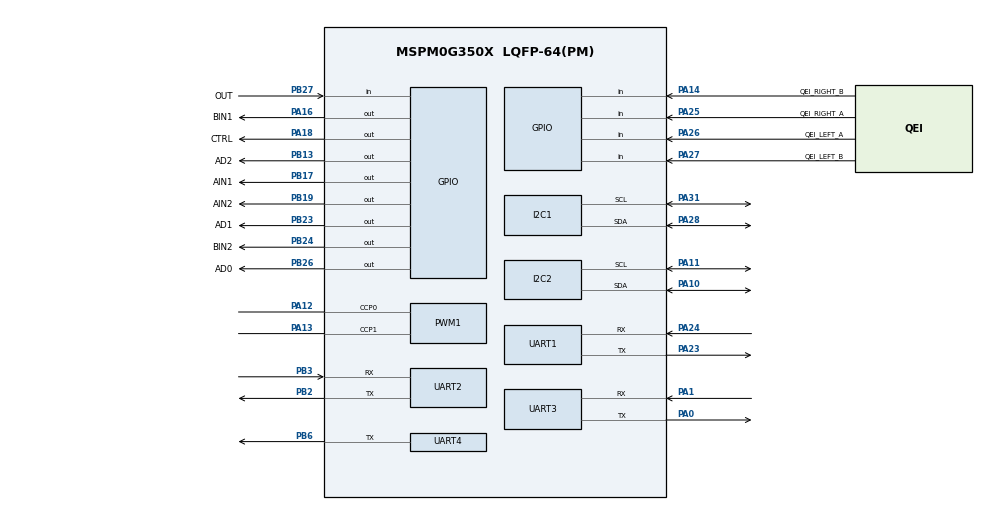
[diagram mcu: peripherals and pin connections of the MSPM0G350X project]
/**
 * @cliArgs --device "MSPM0G350X" --part "Default" --package "LQFP-64(PM)" --product "mspm0_sdk@2.11.00.07"
 * @versions {"tool":"1.26.2+4477"}
 */

/**
 * Import the modules used in this configuration.
 */
const GPIO   = scripting.addModule("/ti/driverlib/GPIO", {}, false);
const GPIO1  = GPIO.addInstance();
const GPIO2  = GPIO.addInstance();
const GPIO3  = GPIO.addInstance();
const GPIO4  = GPIO.addInstance();
const I2C    = scripting.addModule("/ti/driverlib/I2C", {}, false);
const I2C1   = I2C.addInstance();
const I2C2   = I2C.addInstance();
const PWM    = scripting.addModule("/ti/driverlib/PWM", {}, false);
const PWM1   = PWM.addInstance();
const SYSCTL = scripting.addModule("/ti/driverlib/SYSCTL");
const TIMER  = scripting.addModule("/ti/driverlib/TIMER", {}, false);
const TIMER1 = TIMER.addInstance();
const TIMER2 = TIMER.addInstance();
const UART   = scripting.addModule("/ti/driverlib/UART", {}, false);
const UART1  = UART.addInstance();
const UART2  = UART.addInstance();
const UART3  = UART.addInstance();
const UART4  = UART.addInstance();

/**
 * Write custom configuration values to the imported modules.
 */
GPIO1.$name                         = "GPIO_MOTOR";
GPIO1.associatedPins.create(4);
GPIO1.associatedPins[0].$name       = "AIN1";
GPIO1.associatedPins[0].pin.$assign = "PB17";
GPIO1.associatedPins[1].$name       = "AIN2";
GPIO1.associatedPins[1].pin.$assign = "PB19";
GPIO1.associatedPins[2].$name       = "BIN1";
GPIO1.associatedPins[2].pin.$assign = "PA16";
GPIO1.associatedPins[3].$name       = "BIN2";
GPIO1.associatedPins[3].pin.$assign = "PB24";

const Board = scripting.addModule("/ti/driverlib/Board", {}, false);

GPIO2.$name                         = "GPIO_SENSOR";
GPIO2.associatedPins.create(4);
GPIO2.associatedPins[0].$name       = "AD0";
GPIO2.associatedPins[0].pin.$assign = "PB26";
GPIO2.associatedPins[1].$name       = "AD1";
GPIO2.associatedPins[1].pin.$assign = "PB23";
GPIO2.associatedPins[2].$name       = "AD2";
GPIO2.associatedPins[2].pin.$assign = "PB13";
GPIO2.associatedPins[3].$name       = "OUT";
GPIO2.associatedPins[3].direction   = "INPUT";
GPIO2.associatedPins[3].pin.$assign = "PB27";

GPIO3.$name                              = "GPIO_ENCODER";
GPIO3.associatedPins.create(4);
GPIO3.associatedPins[0].$name            = "QEI_LEFT_A";
GPIO3.associatedPins[0].direction        = "INPUT";
GPIO3.associatedPins[0].interruptEn      = true;
GPIO3.associatedPins[0].internalResistor = "PULL_UP";
GPIO3.associatedPins[0].polarity         = "RISE_FALL";
GPIO3.associatedPins[0].pin.$assign      = "PA26";
GPIO3.associatedPins[1].$name            = "QEI_RIGHT_A";
GPIO3.associatedPins[1].direction        = "INPUT";
GPIO3.associatedPins[1].interruptEn      = true;
GPIO3.associatedPins[1].internalResistor = "PULL_UP";
GPIO3.associatedPins[1].polarity         = "RISE_FALL";
GPIO3.associatedPins[1].pin.$assign      = "PA25";
GPIO3.associatedPins[2].$name            = "QEI_LEFT_B";
GPIO3.associatedPins[2].direction        = "INPUT";
GPIO3.associatedPins[2].internalResistor = "PULL_UP";
GPIO3.associatedPins[2].pin.$assign      = "PA27";
GPIO3.associatedPins[3].$name            = "QEI_RIGHT_B";
GPIO3.associatedPins[3].direction        = "INPUT";
GPIO3.associatedPins[3].internalResistor = "PULL_UP";
GPIO3.associatedPins[3].pin.$assign      = "PA14";

GPIO4.$name                         = "GPIO_ELECTROMAGNET";
GPIO4.associatedPins[0].$name       = "CTRL";
GPIO4.associatedPins[0].pin.$assign = "PA18";

I2C1.$name                             = "OLED";
I2C1.basicEnableController             = true;
I2C1.advDigitalGlitchFilter            = "CLOCKS_1";
I2C1.advControllerRXFIFOTRIG           = "BYTES_8";
I2C1.advControllerTXFIFOTRIG           = "BYTES_7";
I2C1.enableDMAEvent1                   = false;
I2C1.enableDMAEvent2                   = false;
I2C1.peripheral.$assign                = "I2C0";
I2C1.peripheral.sdaPin.$assign         = "PA28";
I2C1.peripheral.sclPin.$assign         = "PA31";
I2C1.sdaPinConfig.hideOutputInversion  = scripting.forceWrite(false);
I2C1.sdaPinConfig.onlyInternalResistor = scripting.forceWrite(false);
I2C1.sdaPinConfig.passedPeripheralType = scripting.forceWrite("Digital");
I2C1.sdaPinConfig.$name                = "ti_driverlib_gpio_GPIOPinGeneric2";
I2C1.sdaPinConfig.enableConfig         = true;
I2C1.sdaPinConfig.internalResistor     = "PULL_UP";
I2C1.sclPinConfig.hideOutputInversion  = scripting.forceWrite(false);
I2C1.sclPinConfig.onlyInternalResistor = scripting.forceWrite(false);
I2C1.sclPinConfig.passedPeripheralType = scripting.forceWrite("Digital");
I2C1.sclPinConfig.$name                = "ti_driverlib_gpio_GPIOPinGeneric3";
I2C1.sclPinConfig.enableConfig         = true;
I2C1.sclPinConfig.internalResistor     = "PULL_UP";

I2C2.$name                             = "MT6701_I2C";
I2C2.basicEnableController             = true;
I2C2.advDigitalGlitchFilter            = "CLOCKS_1";
I2C2.advControllerTXFIFOTRIG           = "BYTES_1";
I2C2.enableDMAEvent1                   = false;
I2C2.enableDMAEvent2                   = false;
I2C2.peripheral.$assign                = "I2C1";
I2C2.peripheral.sdaPin.$assign         = "PA10";
I2C2.peripheral.sclPin.$assign         = "PA11";
I2C2.sdaPinConfig.hideOutputInversion  = scripting.forceWrite(false);
I2C2.sdaPinConfig.onlyInternalResistor = scripting.forceWrite(false);
I2C2.sdaPinConfig.passedPeripheralType = scripting.forceWrite("Digital");
I2C2.sdaPinConfig.$name                = "ti_driverlib_gpio_GPIOPinGeneric8";
I2C2.sdaPinConfig.enableConfig         = true;
I2C2.sdaPinConfig.internalResistor     = "PULL_UP";
I2C2.sclPinConfig.hideOutputInversion  = scripting.forceWrite(false);
I2C2.sclPinConfig.onlyInternalResistor = scripting.forceWrite(false);
I2C2.sclPinConfig.passedPeripheralType = scripting.forceWrite("Digital");
I2C2.sclPinConfig.$name                = "ti_driverlib_gpio_GPIOPinGeneric9";
I2C2.sclPinConfig.enableConfig         = true;
I2C2.sclPinConfig.internalResistor     = "PULL_UP";

PWM1.$name                              = "PWM_MOTOR";
PWM1.pwmMode                            = "EDGE_ALIGN_UP";
PWM1.timerCount                         = 2000;
PWM1.peripheral.$assign                 = "TIMG0";
PWM1.peripheral.ccp0Pin.$assign         = "PA12";
PWM1.peripheral.ccp1Pin.$assign         = "PA13";
PWM1.PWM_CHANNEL_0.$name                = "ti_driverlib_pwm_PWMTimerCC0";
PWM1.PWM_CHANNEL_1.$name                = "ti_driverlib_pwm_PWMTimerCC1";
PWM1.ccp0PinConfig.direction            = scripting.forceWrite("OUTPUT");
PWM1.ccp0PinConfig.hideOutputInversion  = scripting.forceWrite(false);
PWM1.ccp0PinConfig.onlyInternalResistor = scripting.forceWrite(false);
PWM1.ccp0PinConfig.passedPeripheralType = scripting.forceWrite("Digital");
PWM1.ccp0PinConfig.$name                = "ti_driverlib_gpio_GPIOPinGeneric0";
PWM1.ccp1PinConfig.direction            = scripting.forceWrite("OUTPUT");
PWM1.ccp1PinConfig.hideOutputInversion  = scripting.forceWrite(false);
PWM1.ccp1PinConfig.onlyInternalResistor = scripting.forceWrite(false);
PWM1.ccp1PinConfig.passedPeripheralType = scripting.forceWrite("Digital");
PWM1.ccp1PinConfig.$name                = "ti_driverlib_gpio_GPIOPinGeneric1";

SYSCTL.forceDefaultClkConfig = true;
SYSCTL.clockTreeEn           = true;

TIMER1.$name            = "TIMER_0";
TIMER1.interrupts       = ["ZERO"];
TIMER1.timerMode        = "PERIODIC";
TIMER1.timerPeriod      = "10 ms";
TIMER1.timerClkPrescale = 256;

TIMER2.$name            = "PD42S1_PWM";
TIMER2.timerMode        = "PERIODIC_UP";
TIMER2.timerPeriod      = "20 ms";
TIMER2.timerClkPrescale = 32;

UART1.$name                            = "VOFA";
UART1.targetBaudRate                   = 115200;
UART1.enabledInterrupts                = ["RX"];
UART1.peripheral.$assign               = "UART2";
UART1.peripheral.rxPin.$assign         = "PA24";
UART1.peripheral.txPin.$assign         = "PA23";
UART1.txPinConfig.$name                = "ti_driverlib_gpio_GPIOPinGeneric6";
UART1.txPinConfig.direction            = scripting.forceWrite("OUTPUT");
UART1.txPinConfig.hideOutputInversion  = scripting.forceWrite(false);
UART1.txPinConfig.onlyInternalResistor = scripting.forceWrite(false);
UART1.txPinConfig.passedPeripheralType = scripting.forceWrite("Digital");
UART1.rxPinConfig.$name                = "ti_driverlib_gpio_GPIOPinGeneric7";
UART1.rxPinConfig.hideOutputInversion  = scripting.forceWrite(false);
UART1.rxPinConfig.onlyInternalResistor = scripting.forceWrite(false);
UART1.rxPinConfig.passedPeripheralType = scripting.forceWrite("Digital");
UART1.rxPinConfig.enableConfig         = true;
UART1.rxPinConfig.internalResistor     = "PULL_UP";

UART2.$name                            = "IMU601";
UART2.targetBaudRate                   = 115200;
UART2.enabledInterrupts                = ["RX"];
UART2.peripheral.$assign               = "UART3";
UART2.peripheral.rxPin.$assign         = "PB3";
UART2.peripheral.txPin.$assign         = "PB2";
UART2.txPinConfig.direction            = scripting.forceWrite("OUTPUT");
UART2.txPinConfig.hideOutputInversion  = scripting.forceWrite(false);
UART2.txPinConfig.onlyInternalResistor = scripting.forceWrite(false);
UART2.txPinConfig.passedPeripheralType = scripting.forceWrite("Digital");
UART2.txPinConfig.$name                = "ti_driverlib_gpio_GPIOPinGeneric4";
UART2.rxPinConfig.hideOutputInversion  = scripting.forceWrite(false);
UART2.rxPinConfig.onlyInternalResistor = scripting.forceWrite(false);
UART2.rxPinConfig.passedPeripheralType = scripting.forceWrite("Digital");
UART2.rxPinConfig.$name                = "ti_driverlib_gpio_GPIOPinGeneric5";

UART3.$name                            = "VISION_UART";
UART3.targetBaudRate                   = 115200;
UART3.enabledInterrupts                = ["RX"];
UART3.peripheral.$assign               = "UART0";
UART3.peripheral.txPin.$assign         = "PA0";
UART3.peripheral.rxPin.$assign         = "PA1";
UART3.txPinConfig.$name                = "ti_driverlib_gpio_GPIOPinGeneric10";
UART3.txPinConfig.direction            = scripting.forceWrite("OUTPUT");
UART3.txPinConfig.hideOutputInversion  = scripting.forceWrite(false);
UART3.txPinConfig.onlyInternalResistor = scripting.forceWrite(false);
UART3.txPinConfig.passedPeripheralType = scripting.forceWrite("Digital");
UART3.rxPinConfig.$name                = "ti_driverlib_gpio_GPIOPinGeneric11";
UART3.rxPinConfig.hideOutputInversion  = scripting.forceWrite(false);
UART3.rxPinConfig.onlyInternalResistor = scripting.forceWrite(false);
UART3.rxPinConfig.passedPeripheralType = scripting.forceWrite("Digital");
UART3.rxPinConfig.enableConfig         = true;
UART3.rxPinConfig.internalResistor     = "NONE";

UART4.$name                            = "PD42S1_UART";
UART4.targetBaudRate                   = 115200;
UART4.enabledInterrupts                = [];
UART4.peripheral.$assign               = "UART1";
UART4.peripheral.txPin.$assign         = "PB6";

/**
 * Pinmux solution for unlocked pins/peripherals. This ensures that minor changes to the automatic solver in a future
 * version of the tool will not impact the pinmux you originally saw.  These lines can be completely deleted in order to
 * re-solve from scratch.
 */
Board.peripheral.$suggestSolution          = "DEBUGSS";
Board.peripheral.swclkPin.$suggestSolution = "PA20";
Board.peripheral.swdioPin.$suggestSolution = "PA19";
TIMER1.peripheral.$suggestSolution         = "TIMA0";
